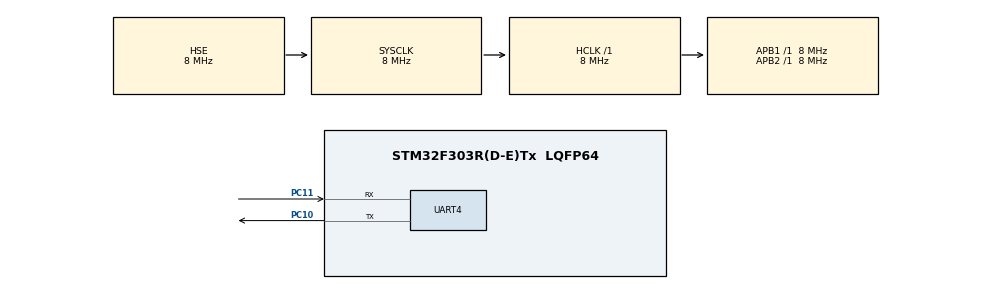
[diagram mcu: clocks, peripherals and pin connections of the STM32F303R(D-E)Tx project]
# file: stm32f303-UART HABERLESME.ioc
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Mcu.Family=STM32F3
Mcu.Name=STM32F303R(D-E)Tx
Mcu.Package=LQFP64
NVIC.PriorityGroup=NVIC_PRIORITYGROUP_4
NVIC.UART4_IRQn=true\:0\:0\:false\:false\:true\:true\:true
PA13.Mode=Serial_Wire
PA13.Signal=SYS_JTMS-SWDIO
PA14.Mode=Serial_Wire
PA14.Signal=SYS_JTCK-SWCLK
PC10.Mode=Asynchronous
PC10.Signal=UART4_TX
PC11.Mode=Asynchronous
PC11.Signal=UART4_RX
PF0-OSC_IN.Mode=HSE-External-Oscillator
PF0-OSC_IN.Signal=RCC_OSC_IN
PF1-OSC_OUT.Mode=HSE-External-Oscillator
PF1-OSC_OUT.Signal=RCC_OSC_OUT
ProjectManager.HeapSize=0x200
ProjectManager.StackSize=0x400
ProjectManager.TargetToolchain=STM32CubeIDE
RCC.AHBFreq_Value=8000000
RCC.APB1Freq_Value=8000000
RCC.APB2Freq_Value=8000000
RCC.CortexFreq_Value=8000000
RCC.HSE_VALUE=8000000
RCC.HSI_VALUE=8000000
RCC.LSE_VALUE=32768
RCC.SYSCLKFreq_VALUE=8000000
RCC.SYSCLKSourceVirtual=RCC_SYSCLKSOURCE_HSE
RCC.USBFreq_Value=16000000
board=custom

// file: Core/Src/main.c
/* USER CODE BEGIN Header */
/**
  ******************************************************************************
  * @file           : main.c
  * @brief          : Main program body
  ******************************************************************************
  * @attention
  *
  * <h2><center>&copy; Copyright (c) 2021 STMicroelectronics.
  * All rights reserved.</center></h2>
  *
  * This software component is licensed by ST under BSD 3-Clause license,
  * the "License"; You may not use this file except in compliance with the
  * License. You may obtain a copy of the License at:
  *                        opensource.org/licenses/BSD-3-Clause
  *
  ******************************************************************************
  */
/* USER CODE END Header */

#include "main.h"

UART_HandleTypeDef huart4;

void SystemClock_Config(void);
static void MX_GPIO_Init(void);
static void MX_UART4_Init(void);

/* USER CODE BEGIN 0 */
uint8_t aRxBuffer[10];

/* USER CODE END 0 */

int main(void)
{

  /* MCU Configuration--------------------------------------------------------*/

  /* Reset of all peripherals, Initializes the Flash interface and the Systick. */
  HAL_Init();

  /* Configure the system clock */
  SystemClock_Config();

  /* Initialize all configured peripherals */
  MX_GPIO_Init();
  MX_UART4_Init();

  /* Infinite loop */
  while (1)
  {

    /* USER CODE BEGIN 3 */
	  //HAL_UART_Receive(&huart4, data, 10, 1000);

	  HAL_UART_Receive_IT(&huart4, (uint8_t *)aRxBuffer, 7);
	 // if(data != data2) {
	  HAL_UART_Transmit(&huart4, (uint8_t *)aRxBuffer, 7,1000);

	  //HAL_UART_Transmit(&huart4, data1, 10, 1000);
	  //HAL_UART_Transmit(&huart4, "proje", 6, 1000);
	  HAL_Delay(1000);
  }
  /* USER CODE END 3 */
}

void SystemClock_Config(void)
{
  RCC_OscInitTypeDef RCC_OscInitStruct = {0};
  RCC_ClkInitTypeDef RCC_ClkInitStruct = {0};
  RCC_PeriphCLKInitTypeDef PeriphClkInit = {0};

  /** Initializes the CPU, AHB and APB busses clocks
  */
  RCC_OscInitStruct.OscillatorType = RCC_OSCILLATORTYPE_HSE;
  RCC_OscInitStruct.HSEState = RCC_HSE_ON;
  RCC_OscInitStruct.HSIState = RCC_HSI_ON;
  RCC_OscInitStruct.PLL.PLLState = RCC_PLL_NONE;
  if (HAL_RCC_OscConfig(&RCC_OscInitStruct) != HAL_OK)
  {
    Error_Handler();
  }
  /** Initializes the CPU, AHB and APB busses clocks
  */
  RCC_ClkInitStruct.ClockType = RCC_CLOCKTYPE_HCLK|RCC_CLOCKTYPE_SYSCLK
                              |RCC_CLOCKTYPE_PCLK1|RCC_CLOCKTYPE_PCLK2;
  RCC_ClkInitStruct.SYSCLKSource = RCC_SYSCLKSOURCE_HSE;
  RCC_ClkInitStruct.AHBCLKDivider = RCC_SYSCLK_DIV1;
  RCC_ClkInitStruct.APB1CLKDivider = RCC_HCLK_DIV1;
  RCC_ClkInitStruct.APB2CLKDivider = RCC_HCLK_DIV1;

  if (HAL_RCC_ClockConfig(&RCC_ClkInitStruct, FLASH_LATENCY_0) != HAL_OK)
  {
    Error_Handler();
  }
  PeriphClkInit.PeriphClockSelection = RCC_PERIPHCLK_UART4;
  PeriphClkInit.Uart4ClockSelection = RCC_UART4CLKSOURCE_PCLK1;
  if (HAL_RCCEx_PeriphCLKConfig(&PeriphClkInit) != HAL_OK)
  {
    Error_Handler();
  }
}

static void MX_UART4_Init(void)
{

  huart4.Instance = UART4;
  huart4.Init.BaudRate = 115200;
  huart4.Init.WordLength = UART_WORDLENGTH_8B;
  huart4.Init.StopBits = UART_STOPBITS_1;
  huart4.Init.Parity = UART_PARITY_NONE;
  huart4.Init.Mode = UART_MODE_TX_RX;
  huart4.Init.HwFlowCtl = UART_HWCONTROL_NONE;
  huart4.Init.OverSampling = UART_OVERSAMPLING_16;
  huart4.Init.OneBitSampling = UART_ONE_BIT_SAMPLE_DISABLE;
  huart4.AdvancedInit.AdvFeatureInit = UART_ADVFEATURE_NO_INIT;
  if (HAL_UART_Init(&huart4) != HAL_OK)
  {
    Error_Handler();
  }

}

static void MX_GPIO_Init(void)
{

  /* GPIO Ports Clock Enable */
  __HAL_RCC_GPIOF_CLK_ENABLE();
  __HAL_RCC_GPIOA_CLK_ENABLE();
  __HAL_RCC_GPIOC_CLK_ENABLE();

}

/* USER CODE BEGIN 4 */
void HAL_UART_RxCpltCallback(UART_HandleTypeDef *huart)
{
  /* Prevent unused argument(s) compilation warning */
  UNUSED(huart);

  /* NOTE : This function should not be modified, when the callback is needed,
            the HAL_UART_RxCpltCallback can be implemented in the user file
   */
    HAL_UART_Transmit(&huart4, (uint8_t *)aRxBuffer, 10,0xFFFF);
}
/* USER CODE END 4 */

void Error_Handler(void)
{
}

/************************ (C) COPYRIGHT STMicroelectronics *****END OF FILE****/
